# LM4F212H5BB register map
File version: 9385
Registers are 32-bit, read-write, no defined reset value unless marked. A register's access mark holds for its fields unless they carry their own. Offsets are from the block's base; [hi:lo] are bit positions; {n}, {i} and the like mark numbered series.

## WATCHDOG0 — Register map for WATCHDOG0 peripheral
Base 0x40000000; register names take the prefix WATCHDOG0
Same registers: WATCHDOG1 0x40001000 (register names take the prefix WATCHDOG1)
0x00 LOAD — Watchdog Load
  [31:0] WDT_LOAD — Watchdog Load Value
0x04 VALUE — Watchdog Value
  [31:0] WDT_VALUE
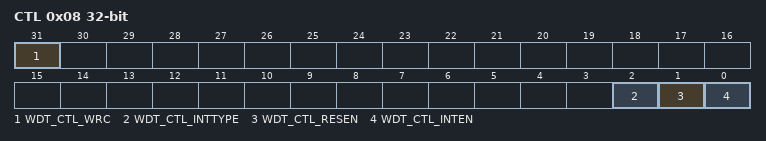
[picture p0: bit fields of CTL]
0x08 CTL — Watchdog Control
  [31] WDT_CTL_WRC — Write Complete
  [2] WDT_CTL_INTTYPE — Watchdog Interrupt Type
  [1] WDT_CTL_RESEN — Watchdog Reset Enable
  [0] WDT_CTL_INTEN — Watchdog Interrupt Enable
0x0C ICR wo — Watchdog Interrupt Clear
  [31:0] WDT_ICR
0x10 RIS — Watchdog Raw Interrupt Status
  [0] WDT_RIS_WDTRIS
0x14 MIS — Watchdog Masked Interrupt Status
  [0] WDT_MIS_WDTMIS
0x418 TEST — Watchdog Test
  [8] WDT_TEST_STALL — Watchdog Stall Enable
0xC00 LOCK — Watchdog Lock
  [31:0] WDT_LOCK
    0=WDT_LOCK_UNLOCKED (Unlocked); 1=WDT_LOCK_LOCKED (Locked)

## GPIOA — Register map for GPIOA peripheral
Base 0x40004000; register names take the prefix GPIOA
Same registers: GPIOB 0x40005000 (register names take the prefix GPIOB), GPIOC 0x40006000 (register names take the prefix GPIOC), GPIOD 0x40007000 (register names take the prefix GPIOD), GPIOE 0x40024000 (register names take the prefix GPIOE), GPIOF 0x40025000 (register names take the prefix GPIOF), GPIOG 0x40026000 (register names take the prefix GPIOG), GPIOH 0x40027000 (register names take the prefix GPIOH), GPIOJ 0x4003D000 (register names take the prefix GPIOJ), GPIOA_AHB 0x40058000 (register names take the prefix GPIOA_AHB), GPIOB_AHB 0x40059000 (register names take the prefix GPIOB_AHB), GPIOC_AHB 0x4005A000 (register names take the prefix GPIOC_AHB), GPIOD_AHB 0x4005B000 (register names take the prefix GPIOD_AHB), GPIOE_AHB 0x4005C000 (register names take the prefix GPIOE_AHB), GPIOF_AHB 0x4005D000 (register names take the prefix GPIOF_AHB), GPIOG_AHB 0x4005E000 (register names take the prefix GPIOG_AHB), GPIOH_AHB 0x4005F000 (register names take the prefix GPIOH_AHB), GPIOJ_AHB 0x40060000 (register names take the prefix GPIOJ_AHB), GPIOK 0x40061000 (register names take the prefix GPIOK), GPIOL 0x40062000 (register names take the prefix GPIOL), GPIOM 0x40063000 (register names take the prefix GPIOM), GPION 0x40064000 (register names take the prefix GPION), GPIOP 0x40065000 (register names take the prefix GPIOP), GPIOQ 0x40066000 (register names take the prefix GPIOQ)
0x3FC DATA — GPIO Data
0x400 DIR — GPIO Direction
0x404 IS — GPIO Interrupt Sense
0x408 IBE — GPIO Interrupt Both Edges
0x40C IEV — GPIO Interrupt Event
0x410 IM — GPIO Interrupt Mask
  [7:0] GPIO_IM_GPIO — GPIO Interrupt Mask Enable
0x414 RIS — GPIO Raw Interrupt Status
  [7:0] GPIO_RIS_GPIO — GPIO Interrupt Raw Status
0x418 MIS — GPIO Masked Interrupt Status
  [7:0] GPIO_MIS_GPIO
0x41C ICR wo — GPIO Interrupt Clear
  [7:0] GPIO_ICR_GPIO
0x420 AFSEL — GPIO Alternate Function Select
0x500 DR2R — GPIO 2-mA Drive Select
0x504 DR4R — GPIO 4-mA Drive Select
0x508 DR8R — GPIO 8-mA Drive Select
0x50C ODR — GPIO Open Drain Select
0x510 PUR — GPIO Pull-Up Select
0x514 PDR — GPIO Pull-Down Select
0x518 SLR — GPIO Slew Rate Control Select
0x51C DEN — GPIO Digital Enable
0x520 LOCK — GPIO Lock
  [31:0] GPIO_LOCK
    0=GPIO_LOCK_UNLOCKED (The GPIOCR register is unlocked and may be modified); 1=GPIO_LOCK_LOCKED (The GPIOCR register is locked and may not be modified); 0x4C4F434B=GPIO_LOCK_KEY (Unlocks the GPIO_CR register)
0x524 CR ro — GPIO Commit
0x528 AMSEL — GPIO Analog Mode Select
0x52C PCTL — GPIO Port Control
0x530 ADCCTL — GPIO ADC Control
0x534 DMACTL — GPIO DMA Control
0x538 SI — GPIO Select Interrupt
  [0] GPIO_SI_SUM — Summary Interrupt

## SSI0 — Register map for SSI0 peripheral
Base 0x40008000; register names take the prefix SSI0
Same registers: SSI1 0x40009000 (register names take the prefix SSI1), SSI2 0x4000A000 (register names take the prefix SSI2), SSI3 0x4000B000 (register names take the prefix SSI3)
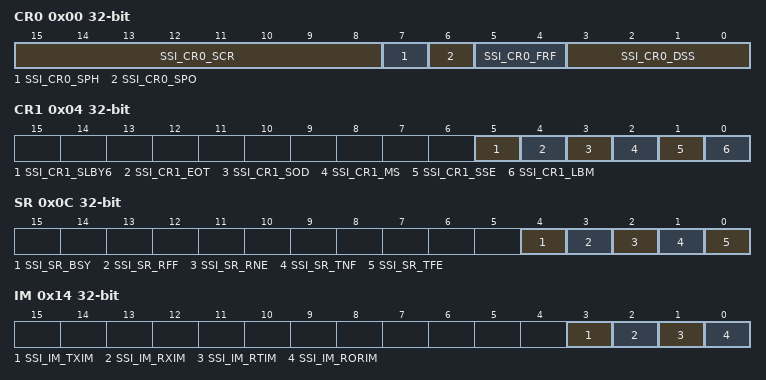
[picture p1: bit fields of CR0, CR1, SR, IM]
0x00 CR0 — SSI Control 0
  [15:8] SSI_CR0_SCR — SSI Serial Clock Rate
  [7] SSI_CR0_SPH — SSI Serial Clock Phase
  [6] SSI_CR0_SPO — SSI Serial Clock Polarity
  [5:4] SSI_CR0_FRF — SSI Frame Format Select
    0=SSI_CR0_FRF_MOTO (Freescale SPI Frame Format); 1=SSI_CR0_FRF_TI (Texas Instruments Synchronous Serial Frame Format); 2=SSI_CR0_FRF_NMW (MICROWIRE Frame Format)
  [3:0] SSI_CR0_DSS — SSI Data Size Select
    {v}={v+1}-bit data (v=3..15)
0x04 CR1 — SSI Control 1
  [5] SSI_CR1_SLBY6 — Slave Bypass Mode
  [4] SSI_CR1_EOT — End of Transmission
  [3] SSI_CR1_SOD — SSI Slave Mode Output Disable
  [2] SSI_CR1_MS — SSI Master/Slave Select
  [1] SSI_CR1_SSE — SSI Synchronous Serial Port Enable
  [0] SSI_CR1_LBM — SSI Loopback Mode
0x08 DR — SSI Data
  [15:0] SSI_DR_DATA — SSI Receive/Transmit Data
0x0C SR — SSI Status
  [4] SSI_SR_BSY — SSI Busy Bit
  [3] SSI_SR_RFF — SSI Receive FIFO Full
  [2] SSI_SR_RNE — SSI Receive FIFO Not Empty
  [1] SSI_SR_TNF — SSI Transmit FIFO Not Full
  [0] SSI_SR_TFE — SSI Transmit FIFO Empty
0x10 CPSR — SSI Clock Prescale
  [7:0] SSI_CPSR_CPSDVSR — SSI Clock Prescale Divisor
0x14 IM — SSI Interrupt Mask
  [3] SSI_IM_TXIM — SSI Transmit FIFO Interrupt Mask
  [2] SSI_IM_RXIM — SSI Receive FIFO Interrupt Mask
  [1] SSI_IM_RTIM — SSI Receive Time-Out Interrupt Mask
  [0] SSI_IM_RORIM — SSI Receive Overrun Interrupt Mask
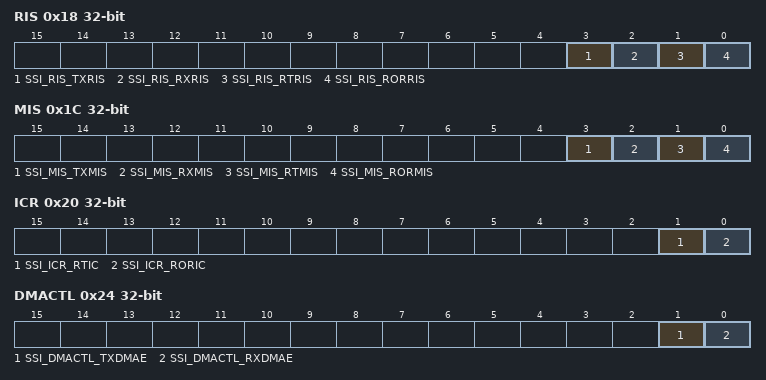
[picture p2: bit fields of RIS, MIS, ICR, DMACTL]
0x18 RIS — SSI Raw Interrupt Status
  [3] SSI_RIS_TXRIS — SSI Transmit FIFO Raw Interrupt Status
  [2] SSI_RIS_RXRIS — SSI Receive FIFO Raw Interrupt Status
  [1] SSI_RIS_RTRIS — SSI Receive Time-Out Raw Interrupt Status
  [0] SSI_RIS_RORRIS — SSI Receive Overrun Raw Interrupt Status
0x1C MIS — SSI Masked Interrupt Status
  [3] SSI_MIS_TXMIS — SSI Transmit FIFO Masked Interrupt Status
  [2] SSI_MIS_RXMIS — SSI Receive FIFO Masked Interrupt Status
  [1] SSI_MIS_RTMIS — SSI Receive Time-Out Masked Interrupt Status
  [0] SSI_MIS_RORMIS — SSI Receive Overrun Masked Interrupt Status
0x20 ICR wo — SSI Interrupt Clear
  [1] SSI_ICR_RTIC — SSI Receive Time-Out Interrupt Clear
  [0] SSI_ICR_RORIC — SSI Receive Overrun Interrupt Clear
0x24 DMACTL — SSI DMA Control
  [1] SSI_DMACTL_TXDMAE — Transmit DMA Enable
  [0] SSI_DMACTL_RXDMAE — Receive DMA Enable
0xFC8 CC — SSI Clock Configuration
  [3:0] SSI_CC_CS — SSI Baud Clock Source
    0=SSI_CC_CS_SYSPLL (Either the system clock (if the PLL bypass is in effect) or the PLL output (default)); 5=SSI_CC_CS_PIOSC (PIOSC)
